# PIC32MK0256MCJ048 device description
Architecture: MIPS; Family: PIC32MK; Series: PIC32MK
Registers are 32-bit, read-write, no defined reset value unless marked. A register's access mark holds for its fields unless they carry their own. Offsets are from the block's base; [hi:lo] are bit positions; 'fields as' and 'values as' point back to an identical list.

## DMT
Instances: DMT 0x1f800e00 in periph_pb1_std
0x00 DMTCON — Deadman Timer Control Register
  [15] ON — Deadman Timer Module Enable bit
    1=Deadman Timer module is enabled; 0=Deadman Timer module is disabled
0x10 DMTPRECLR — Deadman Timer Preclear Register
  [15:8] STEP1 — Preclear Enable bits
    64=Enables the Deadman Timer Preclear (Step 1)
0x20 DMTCLR — Deadman Timer Clear Register
  [7:0] STEP2 — Clear Timer bits
    8=Clears STEP1
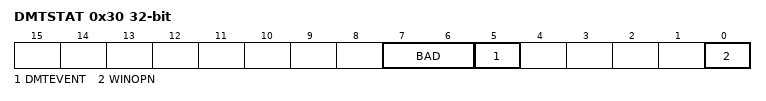
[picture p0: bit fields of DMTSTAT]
0x30 DMTSTAT ro — Deadman Timer Status Register
  [7:6] BAD — Bad STEP2 Value Detect bit
    3=Incorrect STEP1 value was detected/Incorrect STEP2 value was detected; 2=Incorrect STEP1 value was detected/Incorrect STEP2 value was not detected; 1=Incorrect STEP1 value was not detected/Incorrect STEP2 value was detected; 0=Incorrect STEP1 value was not detected/Incorrect STEP2 value was not detected
  [5] DMTEVENT — Deadman Timer Event bit
    1=Deadman timer event was detected (counter expired or bad STEP1 or STEP2 value was entered prior to counter increment); 0=Deadman timer even was not detected
  [0] WINOPN — Deadman Timer Clear Window bit
    1=Deadman timer clear window is open; 0=Deadman timer clear window is not open
0x40 DMTCNT ro — Deadman Timer Count Register
  [31:0] COUNTER
0x60 DMTPSCNT ro — Post Status Configure DMT Count Status Register
  [31:0] PSCNT
0x70 DMTPSINTV ro — Post Status Configure DMT Interval Status Register
  [31:0] PSINTV
Value list DMTSTAT__BAD1: 1=Incorrect STEP1 value was detected; 0=Incorrect STEP1 value was not detected

## HLVD
Instances: HLVD 0x1f801800 in periph_pb1_std
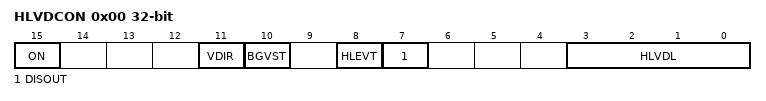
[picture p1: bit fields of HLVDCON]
0x00 HLVDCON — High/Low-Voltage Detect Control Register
  [15] ON — HLVD Module Enable bit
    1=HLVD module is enabled; 0=HLVD module is disabled
  [11] VDIR — Voltage Change Direction Select bit
    1=Event occurs when voltage equals or exceeds the trip point (HLVDL); 0=Event occurs when voltage equals or falls below the trip point (HLVDL)
  [10] BGVST — Band Gap Reference Voltages Stable Status bit
    1=Indicates internal band gap voltage references is stable; 0=Indicates internal band gap voltage reference is not stable
  [8] HLEVT — High/Low-Voltage Detection Event Status bit
    1=Indicates HLVD Event is active; 0=Indicates HLVD Event is not active
  [7] DISOUT — Disable HLVD Output bit
    1=Enable output of HLVD Comparator. Once set, can only be cleared by setting the ON bit to 0.; 0=Disable output of HLVD Comparator (default Reset value)
  [3:0] HLVDL — High/Low-Voltage Detection Limit Select bits
    15=1.2V (Selects external LVDIN pin); 10=2.4V; 9=2.5V; 8=2.69V; 7=2.791V; 6=3.0V; 5=3.288V; 4=3.529V

## ICAP
Instances: ICAP 0x1f822000 in periph_pb2_std
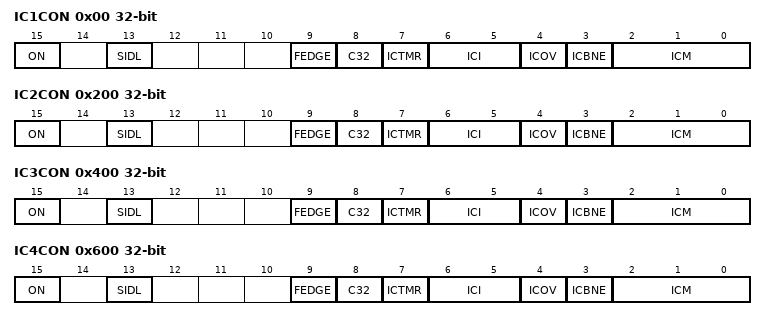
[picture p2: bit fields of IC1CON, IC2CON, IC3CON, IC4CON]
0x00 IC1CON — Input Capture x Control Register
  [15] ON — Input Capture Module Enable bit
    1=Module is enabled; 0=Disable and reset module
  [13] SIDL — Stop in Idle Control bit
    1=Halt in CPU Idle mode; 0=Continue to operate in CPU Idle mode
  [9] FEDGE — First Capture Edge Select bit
    1=Capture rising edge first; 0=Capture falling edge first
  [8] C32 — 32-bit Capture Select bit
    1=32-bit timer resource capture; 0=16-bit timer resource capture
  [7] ICTMR — Timer Select bit
    0=Timery is the counter source for capture; 1=Timerx is the counter source for capture
  [6:5] ICI — Interrupt Control bits
    3=Interrupt on every fourth capture event; 2=Interrupt on every third capture event; 1=Interrupt on every second capture event; 0=Interrupt on every capture event
  [4] ICOV — Input Capture Overflow Status Flag bit
    1=Input capture overflow is occurred; 0=No input capture overflow is occurred
  [3] ICBNE — Input Capture Buffer Not Empty Status bit
    1=Input capture buffer is not empty; at least one more capture value can be read; 0=Input capture buffer is empty
  [2:0] ICM — Input Capture Mode Select bits
    7=Interrupt-Only mode (only supported while in Sleep mode or Idle mode); 6=Simple Capture Event mode every edge; 5=Prescaled Capture Event mode every sixteenth rising edge; 4=Prescaled Capture Event mode every fourth rising edge; 3=Simple Capture Event mode every rising edge; 2=Simple Capture Event mode every falling edge; 1=Edge Detect mode every edge (rising and falling); 0=Input Capture module is disabled
0x10 IC1BUF ro
0x200 IC2CON — Input Capture x Control Register
  fields as IC1CON
0x210 IC2BUF ro
0x400 IC3CON — Input Capture x Control Register
  fields as IC1CON
0x410 IC3BUF ro
0x600 IC4CON — Input Capture x Control Register
  fields as IC1CON
0x610 IC4BUF ro
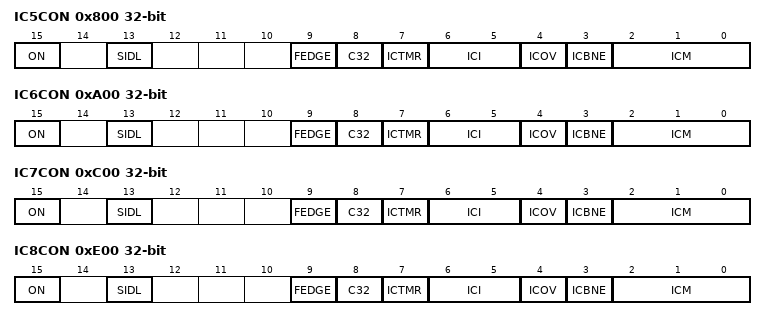
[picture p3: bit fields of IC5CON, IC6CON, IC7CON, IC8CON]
0x800 IC5CON — Input Capture x Control Register
  fields as IC1CON
0x810 IC5BUF ro
0xA00 IC6CON — Input Capture x Control Register
  fields as IC1CON
0xA10 IC6BUF ro
0xC00 IC7CON — Input Capture x Control Register
  fields as IC1CON
0xC10 IC7BUF ro
0xE00 IC8CON — Input Capture x Control Register
  fields as IC1CON
0xE10 IC8BUF ro
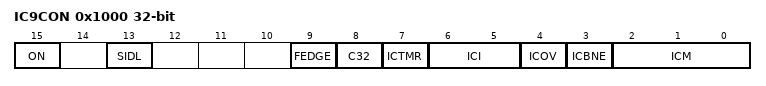
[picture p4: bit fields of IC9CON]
0x1000 IC9CON — Input Capture x Control Register
  fields as IC1CON
0x1010 IC9BUF ro

## Notices in the file
Copyright (c) 2019 Microchip Technology Inc.
SPDX-License-Identifier: Apache-2.0
Licensed under the Apache License, Version 2.0 (the "License");
you may not use this file except in compliance with the License.
You may obtain a copy of the License at
http://www.apache.org/licenses/LICENSE-2.0
Unless required by applicable law or agreed to in writing, software
distributed under the License is distributed on an "AS IS" BASIS,
WITHOUT WARRANTIES OR CONDITIONS OF ANY KIND, either express or implied.
See the License for the specific language governing permissions and
limitations under the License.
